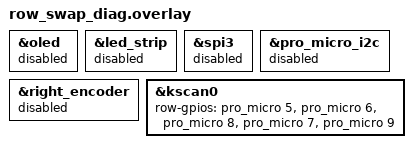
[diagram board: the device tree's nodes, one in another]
/*
 * Diagnostic: swap firmware row index 2 (home) with 3 (N-row) on this half.
 *
 * If MCU pin D8 / pro_micro 8 / P1.04 is dead:
 *   - Physical N M , . / Shift stay dead
 *   - Physical H J K L ; ' type as N M , . / Shift instead
 *
 * If those physical N-row keys start typing home-row letters, D8 works and
 * the fault is elsewhere (columns / transform / central keymap).
 */

&oled {
	status = "disabled";
};

&led_strip {
	status = "disabled";
};

&spi3 {
	status = "disabled";
};

&pro_micro_i2c {
	status = "disabled";
};

&right_encoder {
	status = "disabled";
};

&kscan0 {
	row-gpios
		= <&pro_micro 5 (GPIO_ACTIVE_HIGH | GPIO_PULL_DOWN)>
		, <&pro_micro 6 (GPIO_ACTIVE_HIGH | GPIO_PULL_DOWN)>
		, <&pro_micro 8 (GPIO_ACTIVE_HIGH | GPIO_PULL_DOWN)> /* was 7: home <-> N-row */
		, <&pro_micro 7 (GPIO_ACTIVE_HIGH | GPIO_PULL_DOWN)> /* was 8 */
		, <&pro_micro 9 (GPIO_ACTIVE_HIGH | GPIO_PULL_DOWN)>
		;
};
